# max32662 register map
Vendor: Maxim-Integrated; Series: ARMCM4; File version: 1.1
CPU: CM4 r2p1, little endian, MPU, FPU, 3 interrupt priority bits
Registers are 32-bit, read-write, reset 0x0 unless marked. A register's access mark holds for its fields unless they carry their own. Offsets are from the block's base; [hi:lo] are bit positions; {n}, {i} and the like mark numbered series.

## PTG — Pulse Train Generation
Base 0x4003C000
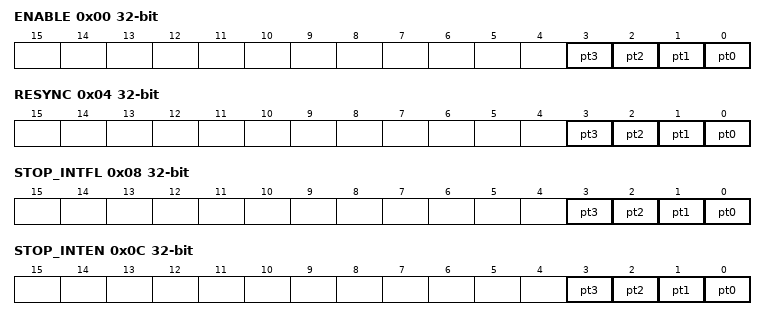
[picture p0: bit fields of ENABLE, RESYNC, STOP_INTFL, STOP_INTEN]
0x00 ENABLE — Global Enable/Disable Controls for All Pulse Trains
  [n] pt{n} (n=0..3) — Enable/Disable control for PT{n}
0x04 RESYNC — Global Resync (All Pulse Trains) Control
  [n] pt{n} (n=0..3) — Resync control for PT{n}
0x08 STOP_INTFL — Pulse Train Stop Interrupt Flags
  [n] pt{n} (n=0..3) — Pulse Train {n} Stopped Interrupt Flag
0x0C STOP_INTEN — Pulse Train Stop Interrupt Enable/Disable
  [n] pt{n} (n=0..3) — Pulse Train {n} Stopped Interrupt Enable/Disable
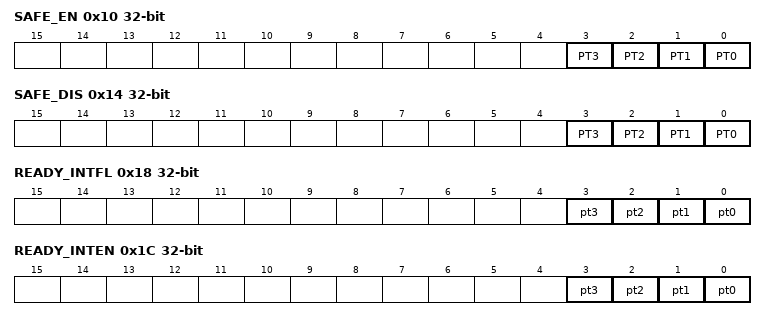
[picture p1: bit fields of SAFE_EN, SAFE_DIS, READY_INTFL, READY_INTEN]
0x10 SAFE_EN wo — Pulse Train Global Safe Enable.
  [n] PT{n} (n=0..3)
0x14 SAFE_DIS wo — Pulse Train Global Safe Disable.
  [n] PT{n} (n=0..3)
0x18 READY_INTFL — Pulse Train Ready Interrupt Flags
  [n] pt{n} (n=0..3) — Pulse Train {n} Ready Interrupt Flag
0x1C READY_INTEN — Pulse Train Ready Interrupt Enable/Disable
  [n] pt{n} (n=0..3) — Pulse Train {n} Ready Interrupt Enable/Disable

## RTC — Real Time Clock and Alarm.
Base 0x40106000
0x00 SEC reset not defined — RTC Second Counter. This register contains the 32-bit second counter.
  [31:0] SEC — Seconds Counter.
0x04 SSEC reset not defined — RTC Sub-second Counter. This counter increments at 256Hz. RTC_SEC is incremented when this register rolls over from 0xFF to 0x00.
  [11:0] SSEC — Sub-Seconds Counter (12-bit).
0x08 TODA reset not defined — Time-of-day Alarm.
  [19:0] TOD_ALARM
0x0C SSECA reset not defined — RTC sub-second alarm. This register contains the reload value for the sub-second alarm.
  [31:0] SSEC_ALARM — This register contains the reload value for the sub-second alarm.
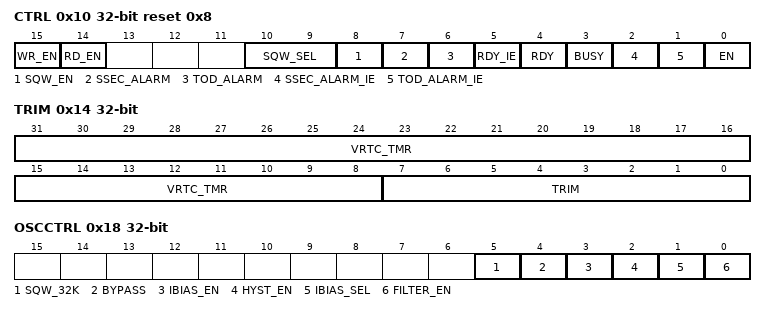
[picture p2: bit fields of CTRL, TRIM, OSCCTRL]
0x10 CTRL reset 0x8 (reset mask 0xFFFFFF38) — RTC Control Register.
  [15] WR_EN — Write Enable. This register bit serves as a protection mechanism against unintentional writes to critical RTC bits.
    0=inactive (Not active); 1=Pending (Active)
  [14] RD_EN — Asynchronous Counter Read Enable.
  [10:9] SQW_SEL — Frequency Output Selection. When SQE=1, these bits specify the output frequency on the SQW pin.
    0=freq1Hz (1 Hz (Compensated).); 1=freq512Hz (512 Hz (Compensated).); 2=freq4KHz (4 KHz.); 3=clkDiv8 (RTC Input Clock / 8.)
  [8] SQW_EN — Square Wave Output Enable.
    0=inactive (Not active); 1=Pending (Active)
  [7] SSEC_ALARM ro — Sub-second Alarm Interrupt Flag. This alarm is qualified as wake-up source to the processor.
    0=inactive (Not active); 1=Pending (Active)
  [6] TOD_ALARM ro — Time-of-Day Alarm Interrupt Flag. This alarm is qualified as wake-up source to the processor.
    0=inactive (Not active); 1=Pending (Active)
  [5] RDY_IE — RTC Ready Interrupt Enable.
    0=dis (Disable.); 1=en (Enable.)
  [4] RDY — RTC Ready. This bit is set to 1 by hardware when the RTC count registers update. It can be cleared to 0 by software at any time. It will also be cleared to 0 by hardware just prior to an update of the RTC count register.
    0=busy (Register has not updated.); 1=ready
  [3] BUSY ro — RTC Busy. This bit is set to 1 by hardware when changes to RTC registers required a synchronized version of the register to be in place. This bit is automatically cleared by hardware.
    0=idle; 1=busy
  [2] SSEC_ALARM_IE — Alarm Sub-second Interrupt Enable. Change to this bit is effective only after BUSY is cleared from 1 to 0.
    0=dis (Disable.); 1=en (Enable.)
  [1] TOD_ALARM_IE — Alarm Time-of-Day Interrupt Enable. Change to this bit is effective only after BUSY is cleared from 1 to 0.
    0=dis (Disable.); 1=en (Enable.)
  [0] EN — Real Time Clock Enable. This bit enables the Real Time Clock. This bit can only be written when WE=1 and BUSY =0. Change to this bit is effective only after BUSY is cleared from 1 to 0.
    0=dis (Disable.); 1=en (Enable.)
0x14 TRIM reset not defined — RTC Trim Register.
  [31:8] VRTC_TMR — VBAT Timer Value. When RTC is running off of VBAT, this field is incremented every 32 seconds.
  [7:0] TRIM — RTC Trim. This register contains the 2's complement value that specifies the trim resolution. Each increment or decrement of the bit adds or subtracts 1ppm at each 4KHz clock value, with a maximum correction of +/- 127ppm.
0x18 OSCCTRL reset not defined — RTC Oscillator Control Register.
  [5] SQW_32K — RTC 32kHz Square Wave Output
  [4] BYPASS — RTC Crystal Bypass
  [3] IBIAS_EN — Enables higher 4x,2x current modes.
  [2] HYST_EN — Enables high current hysteresis buffer.
  [1] IBIAS_SEL — If IBIAS_EN is 1, selects 4x,2x mode.
  [0] FILTER_EN — Enables analog deglitch filter.

## SIR — System Initialization Registers.
Base 0x40000400
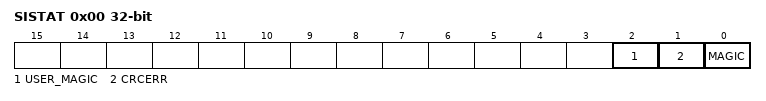
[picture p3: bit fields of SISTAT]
0x00 SISTAT ro — System Initialization Status Register.
  [2] USER_MAGIC — User Magic Word Validation. This bit is set by the system initialization block following power-up.
    on read: 0=userMagicNotSet (User magic word was not set (OTP has not been initialized properly).); 1=userMagicSet (User magic word was set (OTP contains valid settings).)
  [1] CRCERR — CRC Error Status. This bit is set by the system initialization block following power-up.
    on read: 0=noError (No CRC errors occurred during the read of the OTP memory block.); 1=error (A CRC error occurred while reading the OTP. The address of the failure location in the OTP memory is stored in the ERRADDR register.)
  [0] MAGIC — Magic Word Validation. This bit is set by the system initialization block following power-up.
    on read: 0=magicNotSet (Magic word was not set (OTP has not been initialized properly).); 1=magicSet (Magic word was set (OTP contains valid settings).)
0x04 SIADDR ro — System Initialization Address Register.
  [31:0] ERRADDR

## TRIMSIR — Trim System Initilazation Registers
Base 0x40105400
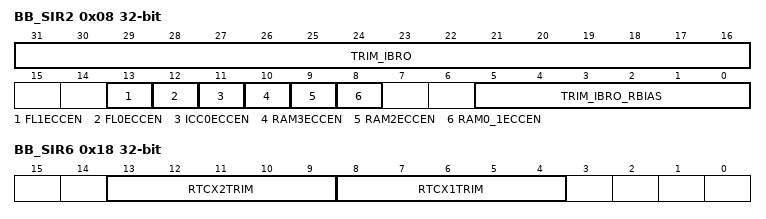
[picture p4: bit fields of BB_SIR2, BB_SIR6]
0x08 BB_SIR2 — System Init. Configuration Register 2.
  [31:16] TRIM_IBRO — HIRC8M Trim
  [13] FL1ECCEN — Flash 1 ECC Enable
    0=dis (ECC Disabled.); 1=en (ECC Enabled.)
  [12] FL0ECCEN — Flash 0 ECC Enable
    0=dis (ECC Disabled.); 1=en (ECC Enabled.)
  [11] ICC0ECCEN — ICC 0 ECC Enable
    0=dis (ECC Disabled.); 1=en (ECC Enabled.)
  [10] RAM3ECCEN — RAM 3 ECC Enable
    0=dis (ECC Disabled.); 1=en (ECC Enabled.)
  [9] RAM2ECCEN — RAM 2 ECC Enable
    0=dis (ECC Disabled.); 1=en (ECC Enabled.)
  [8] RAM0_1ECCEN — RAM 0 and RAM 1 ECC Enable
    0=dis (ECC Disabled.); 1=en (ECC Enabled.)
  [5:0] TRIM_IBRO_RBIAS — HIRC8M Trim
0x0C BB_SIR3 — System Init. Configuration Register 3.
0x18 BB_SIR6 ro — System Init. Configuration Register 6.
  [13:9] RTCX2TRIM, [8:4] RTCX1TRIM

## TRNG — Random Number Generator.
Base 0x4004D000
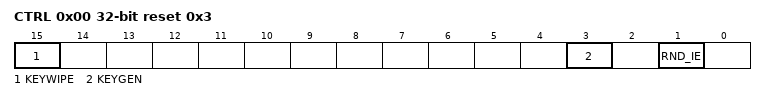
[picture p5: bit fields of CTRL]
0x00 CTRL reset 0x3 — TRNG Control Register.
  [15] KEYWIPE — To wipe the Battery Backed key.
  [3] KEYGEN — AES Key Generate. When enabled, the key for securing NVSRAM is generated and transferred to the secure key register automatically without user visibility or intervention. This bit is cleared by hardware once the key has been transferred to the secure key register.
  [1] RND_IE — To enable IRQ generation when a new 32-bit Random number is ready.
    0=disable; 1=enable
0x04 STATUS — Data. The content of this register is valid only when RNG_IS = 1. When TRNG is disabled, read returns 0x0000 0000.
  [0] RDY — 32-bit random data is ready to read from TRNG_DATA register. Reading TRNG_DATA when RND_RDY=0 will return all 0's. IRQ is generated when RND_RDY=1 if TRNG_CN.RND_IRQ_EN=1.
    0=Busy (TRNG Busy); 1=Ready (32 bit random data is ready)
0x08 DATA ro — Data. The content of this register is valid only when RNG_IS = 1. When TRNG is disabled, read returns 0x0000 0000.
  [31:0] DATA — Data. The content of this register is valid only when RNG_IS =1. When TNRG is disabled, read returns 0x0000 0000.
